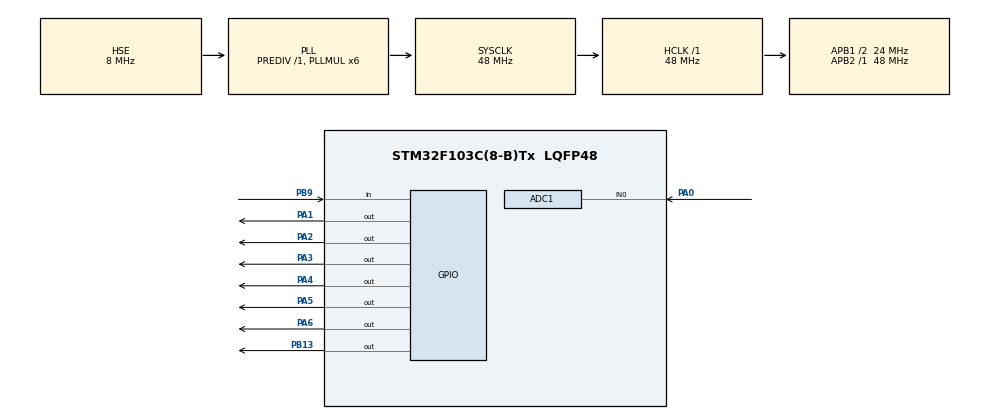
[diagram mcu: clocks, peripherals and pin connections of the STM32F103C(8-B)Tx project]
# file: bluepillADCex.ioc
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ADC1.Channel-3\#ChannelRegularConversion=ADC_CHANNEL_0
ADC1.ContinuousConvMode=ENABLE
ADC1.NbrOfConversionFlag=1
ADC1.Rank-3\#ChannelRegularConversion=1
ADC1.SamplingTime-3\#ChannelRegularConversion=ADC_SAMPLETIME_1CYCLE_5
ADC1.master=1
Mcu.Family=STM32F1
Mcu.Name=STM32F103C(8-B)Tx
Mcu.Package=LQFP48
NVIC.PriorityGroup=NVIC_PRIORITYGROUP_4
PA0-WKUP.Signal=ADCx_IN0
PA1.Signal=GPIO_Output
PA13.Mode=Serial_Wire
PA13.Signal=SYS_JTMS-SWDIO
PA14.Mode=Serial_Wire
PA14.Signal=SYS_JTCK-SWCLK
PA2.Signal=GPIO_Output
PA3.Signal=GPIO_Output
PA4.Signal=GPIO_Output
PA5.Signal=GPIO_Output
PA6.Signal=GPIO_Output
PB13.Signal=GPIO_Output
PB9.Signal=GPIO_Input
PC14-OSC32_IN.Mode=LSE-External-Oscillator
PC14-OSC32_IN.Signal=RCC_OSC32_IN
PC15-OSC32_OUT.Mode=LSE-External-Oscillator
PC15-OSC32_OUT.Signal=RCC_OSC32_OUT
PD0-OSC_IN.Mode=HSE-External-Oscillator
PD0-OSC_IN.Signal=RCC_OSC_IN
PD1-OSC_OUT.Mode=HSE-External-Oscillator
PD1-OSC_OUT.Signal=RCC_OSC_OUT
ProjectManager.HeapSize=0x200
ProjectManager.StackSize=0x400
ProjectManager.TargetToolchain=CMake
RCC.ADCPresc=RCC_ADCPCLK2_DIV4
RCC.AHBFreq_Value=48000000
RCC.APB1CLKDivider=RCC_HCLK_DIV2
RCC.APB1Freq_Value=24000000
RCC.APB1TimFreq_Value=48000000
RCC.APB2Freq_Value=48000000
RCC.APB2TimFreq_Value=48000000
RCC.HCLKFreq_Value=48000000
RCC.PLLMUL=RCC_PLL_MUL6
RCC.PLLSourceVirtual=RCC_PLLSOURCE_HSE
RCC.SYSCLKFreq_VALUE=48000000
RCC.SYSCLKSource=RCC_SYSCLKSOURCE_PLLCLK
RCC.USBFreq_Value=48000000
SH.ADCx_IN0.0=ADC1_IN0,IN0
board=custom

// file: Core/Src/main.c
/* USER CODE BEGIN Header */
/**
 ******************************************************************************
 * @file           : main.c
 * @brief          : Main program body
 ******************************************************************************
 * @attention
 *
 * Copyright (c) 2024 STMicroelectronics.
 * All rights reserved.
 *
 * This software is licensed under terms that can be found in the LICENSE file
 * in the root directory of this software component.
 * If no LICENSE file comes with this software, it is provided AS-IS.
 *
 ******************************************************************************
 */
/* USER CODE END Header */
#include "main.h"
#include "stm32f1xx_hal.h"
#include "stm32f1xx_hal_adc.h"
#include "stm32f1xx_hal_gpio.h"
#include <stdint.h>

ADC_HandleTypeDef hadc1;

void SystemClock_Config(void);
static void MX_GPIO_Init(void);
static void MX_ADC1_Init(void);

int main(void) {

  /* MCU Configuration--------------------------------------------------------*/

  /* Reset of all peripherals, Initializes the Flash interface and the Systick.
   */
  HAL_Init();

  /* Configure the system clock */
  SystemClock_Config();

  /* Initialize all configured peripherals */
  MX_GPIO_Init();
  MX_ADC1_Init();
  /* USER CODE BEGIN 2 */
  HAL_ADC_Start(&hadc1);
  /* USER CODE END 2 */

  /* Infinite loop */
  while (1) {
    HAL_ADC_PollForConversion(&hadc1, 1000);
    uint16_t getVal = HAL_ADC_GetValue(&hadc1);
    uint16_t previousLed = 0;
    uint16_t offLed = 0;
    uint16_t currentLed = 0;
    if (getVal < 100) {
      offLed = GPIO_PIN_1;
    } else if (getVal < 700) {
      currentLed = GPIO_PIN_1;
      offLed = GPIO_PIN_2;
    } else if (getVal < 1400) {
      currentLed = GPIO_PIN_2;
      offLed = GPIO_PIN_3;
    } else if (getVal < 2100) {
      currentLed = GPIO_PIN_3;
      offLed = GPIO_PIN_4;
    } else if (getVal < 2800) {
      currentLed = GPIO_PIN_4;
      offLed = GPIO_PIN_5;
    } else if (getVal < 3500) {
      currentLed = GPIO_PIN_5;
      offLed = GPIO_PIN_6;
    } else if (getVal < 4200) {
      currentLed = GPIO_PIN_6;
    }
    if (currentLed != 0) {
      HAL_GPIO_WritePin(GPIOA, currentLed, GPIO_PIN_SET);
      previousLed = currentLed; // Update the last pin set
    }
    if (offLed != 0) {
      HAL_GPIO_WritePin(GPIOA, offLed, GPIO_PIN_RESET);
    }
    HAL_Delay(20);
  }
}

void SystemClock_Config(void) {
  RCC_OscInitTypeDef RCC_OscInitStruct = {0};
  RCC_ClkInitTypeDef RCC_ClkInitStruct = {0};
  RCC_PeriphCLKInitTypeDef PeriphClkInit = {0};

  /** Initializes the RCC Oscillators according to the specified parameters
   * in the RCC_OscInitTypeDef structure.
   */
  RCC_OscInitStruct.OscillatorType = RCC_OSCILLATORTYPE_HSE;
  RCC_OscInitStruct.HSEState = RCC_HSE_ON;
  RCC_OscInitStruct.HSEPredivValue = RCC_HSE_PREDIV_DIV1;
  RCC_OscInitStruct.HSIState = RCC_HSI_ON;
  RCC_OscInitStruct.PLL.PLLState = RCC_PLL_ON;
  RCC_OscInitStruct.PLL.PLLSource = RCC_PLLSOURCE_HSE;
  RCC_OscInitStruct.PLL.PLLMUL = RCC_PLL_MUL6;
  if (HAL_RCC_OscConfig(&RCC_OscInitStruct) != HAL_OK) {
    Error_Handler();
  }

  /** Initializes the CPU, AHB and APB buses clocks
   */
  RCC_ClkInitStruct.ClockType = RCC_CLOCKTYPE_HCLK | RCC_CLOCKTYPE_SYSCLK |
                                RCC_CLOCKTYPE_PCLK1 | RCC_CLOCKTYPE_PCLK2;
  RCC_ClkInitStruct.SYSCLKSource = RCC_SYSCLKSOURCE_PLLCLK;
  RCC_ClkInitStruct.AHBCLKDivider = RCC_SYSCLK_DIV1;
  RCC_ClkInitStruct.APB1CLKDivider = RCC_HCLK_DIV2;
  RCC_ClkInitStruct.APB2CLKDivider = RCC_HCLK_DIV1;

  if (HAL_RCC_ClockConfig(&RCC_ClkInitStruct, FLASH_LATENCY_1) != HAL_OK) {
    Error_Handler();
  }
  PeriphClkInit.PeriphClockSelection = RCC_PERIPHCLK_ADC;
  PeriphClkInit.AdcClockSelection = RCC_ADCPCLK2_DIV4;
  if (HAL_RCCEx_PeriphCLKConfig(&PeriphClkInit) != HAL_OK) {
    Error_Handler();
  }
}

static void MX_ADC1_Init(void) {

  ADC_ChannelConfTypeDef sConfig = {0};

  /** Common config
   */
  hadc1.Instance = ADC1;
  hadc1.Init.ScanConvMode = ADC_SCAN_DISABLE;
  hadc1.Init.ContinuousConvMode = ENABLE;
  hadc1.Init.DiscontinuousConvMode = DISABLE;
  hadc1.Init.ExternalTrigConv = ADC_SOFTWARE_START;
  hadc1.Init.DataAlign = ADC_DATAALIGN_RIGHT;
  hadc1.Init.NbrOfConversion = 1;
  if (HAL_ADC_Init(&hadc1) != HAL_OK) {
    Error_Handler();
  }

  /** Configure Regular Channel
   */
  sConfig.Channel = ADC_CHANNEL_0;
  sConfig.Rank = ADC_REGULAR_RANK_1;
  sConfig.SamplingTime = ADC_SAMPLETIME_1CYCLE_5;
  if (HAL_ADC_ConfigChannel(&hadc1, &sConfig) != HAL_OK) {
    Error_Handler();
  }
}

static void MX_GPIO_Init(void) {
  GPIO_InitTypeDef GPIO_InitStruct = {0};

  /* GPIO Ports Clock Enable */
  __HAL_RCC_GPIOC_CLK_ENABLE();
  __HAL_RCC_GPIOD_CLK_ENABLE();
  __HAL_RCC_GPIOA_CLK_ENABLE();
  __HAL_RCC_GPIOB_CLK_ENABLE();

  /*Configure GPIO pin Output Level */
  HAL_GPIO_WritePin(GPIOA,
                    GPIO_PIN_1 | GPIO_PIN_2 | GPIO_PIN_3 | GPIO_PIN_4 |
                        GPIO_PIN_5 | GPIO_PIN_6,
                    GPIO_PIN_RESET);

  /*Configure GPIO pin Output Level */
  HAL_GPIO_WritePin(GPIOB, GPIO_PIN_13, GPIO_PIN_RESET);

  /*Configure GPIO pins : PA1 PA2 PA3 PA4
                           PA5 PA6 */
  GPIO_InitStruct.Pin = GPIO_PIN_1 | GPIO_PIN_2 | GPIO_PIN_3 | GPIO_PIN_4 |
                        GPIO_PIN_5 | GPIO_PIN_6;
  GPIO_InitStruct.Mode = GPIO_MODE_OUTPUT_PP;
  GPIO_InitStruct.Pull = GPIO_NOPULL;
  GPIO_InitStruct.Speed = GPIO_SPEED_FREQ_LOW;
  HAL_GPIO_Init(GPIOA, &GPIO_InitStruct);

  /*Configure GPIO pin : PB13 */
  GPIO_InitStruct.Pin = GPIO_PIN_13;
  GPIO_InitStruct.Mode = GPIO_MODE_OUTPUT_PP;
  GPIO_InitStruct.Pull = GPIO_NOPULL;
  GPIO_InitStruct.Speed = GPIO_SPEED_FREQ_LOW;
  HAL_GPIO_Init(GPIOB, &GPIO_InitStruct);

  /*Configure GPIO pin : PB9 */
  GPIO_InitStruct.Pin = GPIO_PIN_9;
  GPIO_InitStruct.Mode = GPIO_MODE_INPUT;
  GPIO_InitStruct.Pull = GPIO_NOPULL;
  HAL_GPIO_Init(GPIOB, &GPIO_InitStruct);

}

void Error_Handler(void) {
  __disable_irq();
  while (1) {
  }
}

#ifdef USE_FULL_ASSERT
/**
 * @brief  Reports the name of the source file and the source line number
 *         where the assert_param error has occurred.
 * @param  file: pointer to the source file name
 * @param  line: assert_param error line source number
 * @retval None
 */
void assert_failed(uint8_t *file, uint32_t line) {
  /* USER CODE BEGIN 6 */
  /* User can add his own implementation to report the file name and line
     number, ex: printf("Wrong parameters value: file %s on line %d\r\n", file,
     line) */
  /* USER CODE END 6 */
}
#endif /* USE_FULL_ASSERT */
